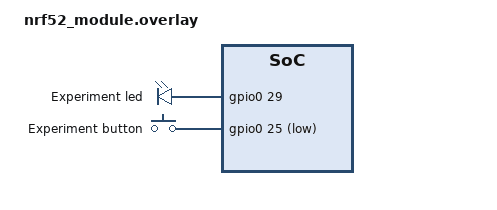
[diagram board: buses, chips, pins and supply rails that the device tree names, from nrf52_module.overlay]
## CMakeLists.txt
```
# SPDX-License-Identifier: Apache-2.0

cmake_minimum_required(VERSION 3.13.1)
find_package(Zephyr HINTS $ENV{ZEPHYR_BASE})
project(lldriver-test)

set(LLBC   ../../../../src/ll)

set(SENSE_VM ../../../../src)       
set(SENSE_VM_H ../../../../include)

set(PLATFORM_SRC ../../../../platform/zephyr/src)
set(PLATFORM_H   ../../../../platform/zephyr/include)

FILE(GLOB app_sources src/*.c)
FILE(GLOB extra_sources
  ${SENSE_VM}/*.c
  ${LLBC}/ll_driver.c
  ${PLATFORM_SRC}/led.c
  ${PLATFORM_SRC}/uart.c
  ${PLATFORM_SRC}/button.c
  ${PLATFORM_SRC}/sys_time.c
  ${PLATFORM_SRC}/sys_debug_uart.c
  ${PLATFORM_SRC}/svm_zephyr.c)
#  ${LLBC_Z}/powerman.c)

target_sources(app PRIVATE ${app_sources} ${extra_sources})
target_include_directories(app PRIVATE
  .
  ${SENSE_VM_H}
  ${SENSE_VM_H}/sys
  ${PLATFORM_H}
  ${ZEPHYR_BASE}/kernel/include
  ${ZEPHYR_BASE}/arch/${ARCH}/include)


zephyr_library_include_directories(${ZEPHYR_BASE}/samples/bluetooth)
```

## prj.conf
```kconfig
## Loging and asserts
#CONFIG_ASSERT=y
#CONFIG_ASSERT_LEVEL=1
CONFIG_LOG=y
#CONFIG_LOG_PRINTK=y
#CONFIG_LOG_BACKEND_UART=y

CONFIG_RING_BUFFER=y

## CONFIG I2C
#CONFIG_I2C=y

## CONFIG SPI
#CONFIG_SPI=y
##CONFIG_NRFX_SPIM1=y
##CONFIG_SPI_1=y

## Config BME280
#CONFIG_SENSOR=y
#CONFIG_BME280=y

## Counters 
CONFIG_COUNTER=y
CONFIG_COUNTER_TIMER4=y

## Power management
#CONFIG_PM=y
#CONFIG_SYS_POWER_MANAGEMENT=y
#CONFIG_PM_POLICY_APP=y
##CONFIG_MP_NUM_CPUS=1
#CONFIG_CLOCK_CONTROL=y
#CONFIG_CLOCK_CONTROL_NRF=y

## Thread statistics
#CONFIG_THREAD_NAME=y
#CONFIG_THREAD_RUNTIME_STATS=y
#CONFIG_THREAD_MONITOR=y

## CONFIG USB CDC
CONFIG_STDOUT_CONSOLE=y
CONFIG_GPIO=y
#CONFIG_USB=y
#CONFIG_USB_DEVICE_STACK=y
#CONFIG_USB_DEVICE_PRODUCT="Zephyr CDC ACM sample"
#CONFIG_USB_DRIVER_LOG_LEVEL_ERR=y
#CONFIG_USB_CDC_ACM=y
#CONFIG_USB_DEVICE_LOG_LEVEL_ERR=y
CONFIG_SERIAL=y
CONFIG_UART_INTERRUPT_DRIVEN=y
# CONFIG_UART_LINE_CTRL=y



## Configure optimizations
CONFIG_SPEED_OPTIMIZATIONS=y
```

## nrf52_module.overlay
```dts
/ {

  
     leds {
     	  compatible = "gpio-leds";
	  led100: led_100 {
	      	  gpios = <&gpio0 29 GPIO_ACTIVE_HIGH>;
		  label = "Experiment led";
	  };
     };

     buttons {
     	     compatible = "gpio-keys";
	     button100: button_100 {
	     		gpios = <&gpio0 25 (GPIO_PULL_UP | GPIO_ACTIVE_LOW)>;
			label = "Experiment button";
	     };
     };

     aliases {
     	     svm-uart0 = &uart0;

 	     svm-debug-uart = &uart1;

	     svm-led0 = &led100;
	     
	     svm-button0 = &button100;
	     svm-button1 = &button1;
	     svm-button2 = &button2;
	     svm-button3 = &button3;

	     svm-sys-timer = &timer4;
     };
};
```

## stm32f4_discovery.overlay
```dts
/ {
     aliases {
     svm-uart0 = &usart2;

     svm-debug-uart = &usart1;	

     svm-button0 = &user_button;

     svm-led0 = &orange_led_3;
     svm-led1 = &green_led_4;
     svm-led2 = &red_led_5;
     svm-led3 = &blue_led_6;

     svm-sys-timer = &timers5;
     };
};

&timers5 {
   status = "okay";
  // compare: cc1@0 {
  //   reg = <0>;			/* channel 1 */
  //   compatible = "st,stm32-compare";
  //   label = "TIM5_CC1";
  //   status = "okay";
  // };

};
```

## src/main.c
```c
#include <zephyr/types.h>
#include <stddef.h>
#include <stdio.h>
#include <errno.h>
#include <zephyr.h>
#include <sys/printk.h>

#include <sys/ring_buffer.h>

#include <drivers/gpio.h>
#include <drivers/uart.h>
#include <drivers/i2c.h>
#include <drivers/sensor.h>
#include <drivers/counter.h>

#include <kernel.h>

/* SenseVM include */
#include <svm_zephyr.h> /* <hal/zephyr/svm_zephyr.h> */
#include <vm-conf.h>
//#include <VMC.h>
//#include <CAM.h>

/* Our own library of stuff! */
#include "ll/ll_uart.h"
#include "ll/ll_led.h"

//#include "powerman.h"
//#include "timerman.h"

//#define PRINT usb_printf
#define PRINT printk

/* *************** */
/*   UART buffers  */

uint8_t uart0_in_buffer[1024];
uint8_t uart0_out_buffer[1024];

/* ****************** */
/* Thread info dumper */

static int t_counter = 0;

void t_info_dump(const struct k_thread *cthread, void *user_data) {
  struct k_thread *thread = (struct k_thread *)cthread;
  const char *tname;

  tname = k_thread_name_get(thread);

  PRINT("%s%p %-10s",
	(thread == k_current_get()) ? "*" : " ",
	thread,
	tname ? tname : "NA");
  PRINT("\toptions: 0x%x, priority: %d timeout: %lld",
	thread->base.user_options,
	thread->base.prio,
	thread->base.timeout.dticks);
  PRINT("\tstate: %s\r\n", k_thread_state_str(thread));

  t_counter++;

}

//const struct device *button;

void main(void) {

  PRINT("Pause 2 seconds\r\n");
  k_sleep(K_SECONDS(2));

  PRINT("Initializing SenseVM Runtime System\r\n");
  if (!zephyr_sensevm_init()) {
    PRINT("Error Initializing SenseVM RTS\r\n");
    return;
  }

  PRINT("Number of containers: %d\r\n", VMC_NUM_CONTAINERS);

  PRINT("Starting SenseVM Containers Threads\r\n");
  if (!zephyr_start_container_threads()) {
    PRINT("FAILED! Could not start container threads\r\n");
  }

  k_sleep(K_SECONDS(1));

  while (true) {
    Time t =  sys_time_get_current_ticks();
    printk("%llu\r\n", t);
    k_sleep(K_SECONDS(1));
  }


  
  /* PRINT("Currently running threads:\r\n"); */
  /* k_thread_foreach(t_info_dump, NULL); */


  // int ret = 0;
  
  /* PRINT("Initializing button\r\n"); */
  /* button = device_get_binding(BUTTON0_GPIO_LABEL); */
  /* if (button == NULL) { */
  /*   printk("Error: didn't find %s device\n", BUTTON0_GPIO_LABEL); */
  /*   return; */
  /* } */

  /* ret = gpio_pin_configure(button, BUTTON0_GPIO_PIN, BUTTON0_GPIO_FLAGS); */
  /* if (ret != 0) { */
  /*   printk("Error %d: failed to configure %s pin %d\n", */
  /* 	   ret, BUTTON0_GPIO_LABEL, BUTTON0_GPIO_PIN); */
  /*   return; */
  /* } */
  
  /* ret = gpio_pin_interrupt_configure(button, */
  /* 				     BUTTON0_GPIO_PIN, */
  /* 				     GPIO_INT_EDGE_TO_ACTIVE); */
  /* if (ret != 0) { */
  /*   printk("Error %d: failed to configure interrupt on %s pin %d\n", */
  /* 	   ret, BUTTON0_GPIO_LABEL, BUTTON0_GPIO_PIN); */
  /*   return; */
  /* } */
  
  /* gpio_init_callback(&button_cb_data, button_pressed, BIT(BUTTON0_GPIO_PIN)); */
  /* gpio_add_callback(button, &button_cb_data); */
  /* printk("Set up button at %s pin %d\n", BUTTON0_GPIO_LABEL, BUTTON0_GPIO_PIN); */
  

  
  /* All the stuff below should move into zephyr_sensevm_init   *
   * Potentially the main "thread" can just die here or go      *
   * into an infinite loop that monitors the progress of the    *
   * container threads.                                         */

  /* ******************* */
  /* Configure some LEDs */

  //  ll_driver_t led1;

  /* if (ll_led_init(&led1, 1, 1)) { */
  /*   PRINT("LL_LED: OK init led1\r\n"); */
  /* } else { */
  /*   PRINT("LL_LED: FAILED init led1\r\n"); */
  /* } */

  /* /\* configure uart *\/ */

  /* ll_driver_t uart_drv; */

  /* PRINT("STARTING UARTS\r\n"); */
  /* if (ll_uart_init(&uart_drv, UART_IF0, uart0_in_buffer, 1024, uart0_out_buffer, 1024)) { */
  /*   PRINT("LL_UART: OK!\r\n"); */
  /* } else { */
  /*   PRINT("LL_UART: Failed!\r\n"); */
  /* } */

  /* const char *hello = "hello world\r\n"; */

  /* int i = 0;  */
  /* while (1) { */

  /*   uint8_t led1_state; */

  /*   ll_read(&led1, &led1_state, 1); */

  /*   led1_state = 1 - led1_state; */

  /*   ll_write(&led1, &led1_state, 1); */
    
  /*   k_sleep(K_SECONDS(1)); */
  /*   i++; */
  /* } */

}
```
